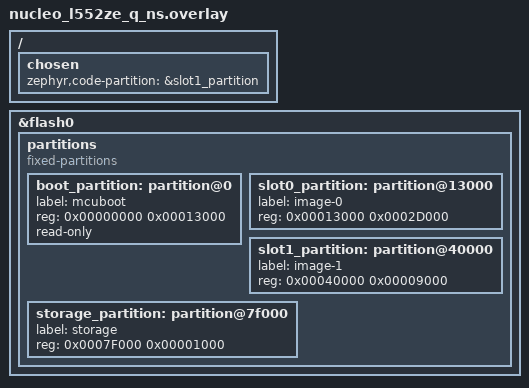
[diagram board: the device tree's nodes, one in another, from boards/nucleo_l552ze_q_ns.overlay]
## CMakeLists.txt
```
# SPDX-License-Identifier: Apache-2.0

cmake_minimum_required(VERSION 3.13.1)

find_package(Zephyr REQUIRED HINTS $ENV{ZEPHYR_BASE})

project(tfm_ipc)

target_sources(app PRIVATE src/main.c)

target_include_directories(app PRIVATE
  ${ZEPHYR_TRUSTED_FIRMWARE_M_MODULE_DIR}/trusted-firmware-m/interface/include
)
```

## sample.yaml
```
sample:
    description: This app provides an example of using TF-M on the secure
        side, with Zephyr on the NS side, using IPC.
    name: TF-M IPC example
tests:
    sample.tfm_ipc:
        tags: introduction tfm
        platform_allow: mps2_an521_nonsecure lpcxpresso55s69_ns
          nrf5340dk_nrf5340_cpuappns nrf9160dk_nrf9160ns nucleo_l552ze_q_ns
          stm32l562e_dk_ns v2m_musca_s1_nonsecure v2m_musca_b1_nonsecure bl5340_dvk_cpuappns
        harness: console
        harness_config:
          type: multi_line
          regex:
            - "The version of the PSA Framework API is"
            - "The minor version is"
            - "Connect success!"
            - "TF-M IPC on .*"
```

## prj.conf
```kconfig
CONFIG_BUILD_WITH_TFM=y
CONFIG_TFM_IPC=y
CONFIG_TFM_PARTITION_AUDIT_LOG=n
CONFIG_REBOOT=y

# The Zephyr CMSIS emulation assumes that ticks are ms, currently
CONFIG_SYS_CLOCK_TICKS_PER_SEC=1000

CONFIG_MAIN_STACK_SIZE=4096
CONFIG_HEAP_MEM_POOL_SIZE=4096
```

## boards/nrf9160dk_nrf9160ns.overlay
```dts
/*
 * Copyright (c) 2020 Nordic Semiconductor ASA.
 *
 * SPDX-License-Identifier: Apache-2.0
 */

/* Modify the SRAM partitioning to accommodate the requirements
 * for the Secure (TF-M) firmware for the configuration that is
 * used in this sample.
 */

/* Increase the size of the Secure Firmware (TF-M).
 * This modification is not required at the moment,
 * since TF-M region definitions are configured
 * statically in the TF-M project.
 */
&sram0_s {
	reg = <0x20000000 DT_SIZE_K(88)>;
};

/* Decrease the size of the Non-Secure Firmware (Zephyr),
 * and move its starting address to the offset expected by
 * TF-M.
 */
/delete-node/ &sram0_ns;
/ {
	reserved-memory {
		sram0_ns: image_ns@20016000 {
			reg = <0x20016000 DT_SIZE_K(168)>;
		};
	};
};

/* Disable UART1, because it is used by default in TF-M */
&uart1 {
	status = "disabled";
};
```

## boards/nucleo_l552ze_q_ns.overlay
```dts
/*
 * Copyright (c) 2020 Linaro Limited.
 *
 * SPDX-License-Identifier: Apache-2.0
 */


 /* This partition table should be used along with TFM configuration:
  * - TEST_S=OFF (NO REGRESSION)
  * - TFM_PSA_API=ON (IPC)
  *
  * In this configuration, TFM binary does not include tests.
  * The partition sizes are compatible with the TF-M platform
  * flash_layout.h.
  */

/ {
	chosen {
		zephyr,code-partition = &slot1_partition;
	};
};

&flash0 {

	partitions {
		compatible = "fixed-partitions";
		#address-cells = <1>;
		#size-cells = <1>;

		boot_partition: partition@0 {
			label = "mcuboot";
			reg = <0x00000000 0x00013000>;
			read-only;
		};
		/* Secure image primary slot */
		slot0_partition: partition@13000 {
			label = "image-0";
			reg = <0x00013000 0x0002D000>;
		};
		/* Non-secure image primary slot */
		slot1_partition: partition@40000 {
			label = "image-1";
			reg = <0x00040000 0x00009000>;
		};
		/*
		 * The flash starting at 0x7F000 and ending at
		 * 0x80000 is reserved for the application.
		 */
		storage_partition: partition@7f000 {
			label = "storage";
			reg = <0x0007F000 0x00001000>;
		};
	};
};
```

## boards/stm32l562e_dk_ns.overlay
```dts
/*
 * Copyright (c) 2021 Yestin Sun
 *
 * SPDX-License-Identifier: Apache-2.0
 */

 /* This partition table should be used along with TFM configuration:
  * - TEST_S=OFF (NO REGRESSION)
  * - TFM_PSA_API=ON (IPC)
  *
  * In this configuration, TFM binary does not include tests.
  * The partition sizes are compatible with the TF-M platform
  * flash_layout.h.
  */

/ {
	chosen {
		zephyr,code-partition = &slot1_partition;
	};
};

&flash0 {

	partitions {
		compatible = "fixed-partitions";
		#address-cells = <1>;
		#size-cells = <1>;

		boot_partition: partition@0 {
			label = "mcuboot";
			reg = <0x00000000 0x00019000>;
			read-only;
		};
		/* Secure image primary slot */
		slot0_partition: partition@19000 {
			label = "image-0";
			reg = <0x00019000 0x00038000>;
		};
		/* Non-secure image primary slot */
		slot1_partition: partition@51000 {
			label = "image-1";
			reg = <0x00051000 0x0002A000>;
		};
		/*
		 * The flash starting at 0x7F000 and ending at
		 * 0x80000 is reserved for the application.
		 */
		storage_partition: partition@7f000 {
			label = "storage";
			reg = <0x0007F000 0x00001000>;
		};
	};
};
```

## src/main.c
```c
/*
 * Copyright (c) 2019,2020, 2021 Linaro Limited
 *
 * SPDX-License-Identifier: Apache-2.0
 */

#include <zephyr.h>
#include <sys/printk.h>
#include <power/reboot.h>

#include "tfm_api.h"
#include "tfm_ns_interface.h"
#ifdef TFM_PSA_API
#include "psa_manifest/sid.h"
#endif

/**
 * \brief Retrieve the version of the PSA Framework API.
 *
 * \note This is a functional test only and doesn't
 *       mean to test all possible combinations of
 *       input parameters and return values.
 */
static void tfm_ipc_test_01(void)
{
	uint32_t version;

	version = psa_framework_version();
	if (version == PSA_FRAMEWORK_VERSION) {
		printk("The version of the PSA Framework API is %d.\n",
		       version);
	} else {
		printk("The version of the PSA Framework API is not valid!\n");
		return;
	}
}

/**
 * Retrieve the minor version of a RoT Service.
 *
 * @return N/A
 */
static void tfm_ipc_test_02(void)
{
	uint32_t version;

	version = psa_version(TFM_CRYPTO_SID);
	if (version == PSA_VERSION_NONE) {
		printk("RoT Service is not implemented or caller is not ");
		printk("authorized to access it!\n");
		return;
	}

	/* Valid version number */
	printk("The minor version is %d.\n", version);
}

/**
 * Connect to a RoT Service by its SID.
 *
 * @return N/A
 */
static void tfm_ipc_test_03(void)
{
	psa_handle_t handle;

	handle = psa_connect(TFM_CRYPTO_SID,
			     TFM_CRYPTO_VERSION);
	if (handle > 0) {
		printk("Connect success!\n");
	} else {
		printk("The RoT Service has refused the connection!\n");
		return;
	}
	psa_close(handle);
}

void main(void)
{
	tfm_ipc_test_01();
	tfm_ipc_test_02();
	tfm_ipc_test_03();

	printk("TF-M IPC on %s\n", CONFIG_BOARD);

	k_sleep(K_MSEC(5000));
	sys_reboot(0);
}
```
